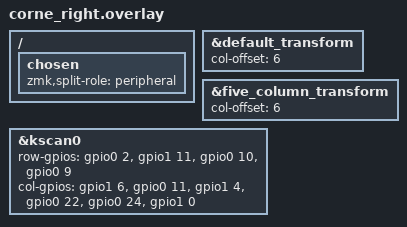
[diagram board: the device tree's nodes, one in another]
#include "corne.dtsi"

/ {
    chosen {
        zmk,split-role = "peripheral";
    };
};

&default_transform {
    col-offset = <6>;
};

&five_column_transform {
    col-offset = <6>;
};

&kscan0 {
    row-gpios
        = <&gpio0 2 (GPIO_ACTIVE_HIGH | GPIO_PULL_DOWN)>
        , <&gpio1 11 (GPIO_ACTIVE_HIGH | GPIO_PULL_DOWN)>
        , <&gpio0 10 (GPIO_ACTIVE_HIGH | GPIO_PULL_DOWN)>
        , <&gpio0 9 (GPIO_ACTIVE_HIGH | GPIO_PULL_DOWN)>
        ;
    col-gpios
        = <&gpio1 6 GPIO_ACTIVE_HIGH>
        , <&gpio0 11 GPIO_ACTIVE_HIGH>
        , <&gpio1 4 GPIO_ACTIVE_HIGH>
        , <&gpio0 22 GPIO_ACTIVE_HIGH>
        , <&gpio0 24 GPIO_ACTIVE_HIGH>
        , <&gpio1 0 GPIO_ACTIVE_HIGH>
        ;
};
